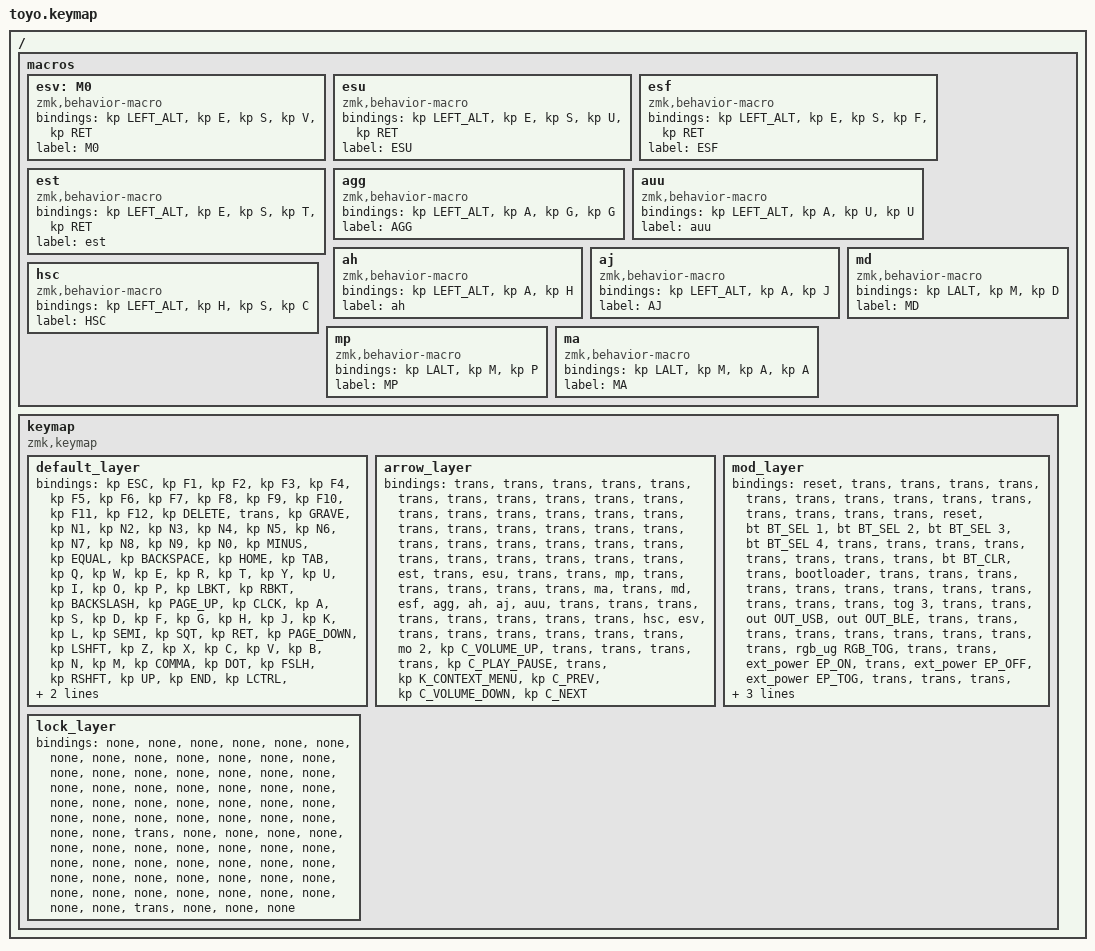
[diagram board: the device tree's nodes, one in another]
/*
 * Copyright (c) 2021 Nick Winans
 *
 * SPDX-License-Identifier: MIT
 */

#include <behaviors.dtsi>
#include <dt-bindings/zmk/bt.h>
#include <dt-bindings/zmk/ext_power.h>
#include <dt-bindings/zmk/keys.h>
#include <dt-bindings/zmk/outputs.h>
#include <dt-bindings/zmk/rgb.h>

/ {
    macros {
        esv: M0 {
            compatible = "zmk,behavior-macro";
            #binding-cells = <0>;
            bindings = <&kp LEFT_ALT &kp E &kp S &kp V &kp RET>;
            label = "M0";
        };

        esu: esu {
            compatible = "zmk,behavior-macro";
            #binding-cells = <0>;
            bindings = <&kp LEFT_ALT &kp E &kp S &kp U &kp RET>;
            label = "ESU";
        };

        esf: esf {
            compatible = "zmk,behavior-macro";
            #binding-cells = <0>;
            bindings = <&kp LEFT_ALT &kp E &kp S &kp F &kp RET>;
            label = "ESF";
        };

        est: est {
            compatible = "zmk,behavior-macro";
            #binding-cells = <0>;
            bindings = <&kp LEFT_ALT &kp E &kp S &kp T &kp RET>;
            label = "est";
        };

        agg: agg {
            compatible = "zmk,behavior-macro";
            #binding-cells = <0>;
            bindings = <&kp LEFT_ALT &kp A &kp G &kp G>;
            label = "AGG";
        };

        auu: auu {
            compatible = "zmk,behavior-macro";
            #binding-cells = <0>;
            bindings = <&kp LEFT_ALT &kp A &kp U &kp U>;
            label = "auu";
        };

        ah: ah {
            compatible = "zmk,behavior-macro";
            #binding-cells = <0>;
            bindings = <&kp LEFT_ALT &kp A &kp H>;
            label = "ah";
        };

        aj: aj {
            compatible = "zmk,behavior-macro";
            #binding-cells = <0>;
            bindings = <&kp LEFT_ALT &kp A &kp J>;
            label = "AJ";
        };

        hsc: hsc {
            compatible = "zmk,behavior-macro";
            #binding-cells = <0>;
            bindings = <&kp LEFT_ALT &kp H &kp S &kp C>;
            label = "HSC";
        };

        md: md {
            compatible = "zmk,behavior-macro";
            #binding-cells = <0>;
            bindings = <&kp LALT &kp M &kp D>;
            label = "MD";
        };

        mp: mp {
            compatible = "zmk,behavior-macro";
            #binding-cells = <0>;
            bindings = <&kp LALT &kp M &kp P>;
            label = "MP";
        };

        ma: ma {
            compatible = "zmk,behavior-macro";
            #binding-cells = <0>;
            bindings = <&kp LALT &kp M &kp A &kp A>;
            label = "MA";
        };
    };

    keymap {
        compatible = "zmk,keymap";

        default_layer {
            // ----------------------------------------------------------------------------------------------------------
            // | F1  | ESC |  1  |  2  |  3  |  4  |  5  |  6  |  7  |  8  |  9  |  0  |  -  |  =  |   BKSP   | HOME    |
            // | F2  | TAB  |  Q  |  W  |  E  |  R  |  T  |  Y  |  U  |  I  |  O  |  P  |  [  |  ]  |   "|"   | PG UP   |
            // | F3  | CAPS  |  A  |  S  | D  |  F  |  G  |  H  |  J  |  K  |  L  |  ;  |  '  |     ENTER     | PG DOWN |
            // | F4  |  SHIFT | SHIFT |  Z  |  X  |  C  |  V  |  B  |  N  |  M  |  ,  |  .  |  /  |   SHIFT  |  UP   | END     |
            // | F5  |  CTL  |  ALT  |  WIN  |                SPACE MO(1)   | MO(1)|  MO(2)  |  LEFT  |  DOWN | RIGHT   |
            // ----------------------------------------------------------------------------------------------------------

            bindings = <
&kp ESC  &kp F1  &kp F2  &kp F3  &kp F4  &kp F5  &kp F6  &kp F7  &kp F8  &kp F9  &kp F10  &kp F11  &kp F12  &kp DELETE  &trans  &kp GRAVE  &kp N1  &kp N2  &kp N3  &kp N4  &kp N5  &kp N6  &kp N7  &kp N8  &kp N9  &kp N0  &kp MINUS  &kp EQUAL  &kp BACKSPACE  &kp HOME  &kp TAB  &kp Q  &kp W  &kp E  &kp R  &kp T  &kp Y  &kp U  &kp I  &kp O  &kp P  &kp LBKT  &kp RBKT  &kp BACKSLASH  &kp PAGE_UP  &kp CLCK  &kp A  &kp S  &kp D  &kp F  &kp G  &kp H  &kp J  &kp K  &kp L  &kp SEMI  &kp SQT  &kp RET  &kp PAGE_DOWN  &kp LSHFT  &kp Z  &kp X  &kp C  &kp V  &kp B  &kp N  &kp M  &kp COMMA  &kp DOT  &kp FSLH  &kp RSHFT  &kp UP  &kp END  &kp LCTRL  &kp LEFT_WIN  &kp LEFT_ALT  &kp SPACE  &mo 1  &kp RIGHT_CONTROL  &kp LEFT  &kp DOWN  &kp RIGHT
            >;
        };

        arrow_layer {
            // ----------------------------------------------------------------------------------------------------------------
            // |        |    |     |     |     |     |     |     |     |     |     |     |     |     |     |   `~    |
            // |        |    |     |     |     |     |     |     |     |     |     |     |     |     |     |         |
            // |        |    |     |     |     |     |     |LEFT |DOWN |  UP |RIGHT|     |     |     |     |         |
            // |        |    |     |     |     |     |     |     |     |     |     |     |     |     |     |         |
            // |        |    |     |     |                                               |     |     |     |         |
            // ----------------------------------------------------------------------------------------------------------------

            bindings = <
&trans  &trans  &trans  &trans  &trans  &trans  &trans  &trans  &trans  &trans  &trans  &trans  &trans  &trans  &trans  &trans  &trans  &trans  &trans  &trans  &trans  &trans  &trans  &trans  &trans  &trans  &trans  &trans  &trans  &trans  &trans  &trans  &trans  &trans  &trans  &est  &trans  &esu  &trans  &trans  &mp  &trans  &trans  &trans  &trans  &trans  &ma  &trans  &md  &esf  &agg  &ah  &aj  &auu  &trans  &trans  &trans  &trans  &trans  &trans  &trans  &trans  &hsc  &esv  &trans  &trans  &trans  &trans  &trans  &trans  &mo 2  &kp C_VOLUME_UP  &trans  &trans  &trans  &trans  &kp C_PLAY_PAUSE  &trans  &kp K_CONTEXT_MENU  &kp C_PREV  &kp C_VOLUME_DOWN  &kp C_NEXT
            >;
        };

        mod_layer {
            // ----------------------------------------------------------------------------------------------------------------
            // |        |    | BT 1|BT 2 |BT 3 |BT 4 |     |     |     |     |     |     |     |     |BT CLR |         |
            // |        |    | RST | BOOT|     |     |     |     |     |     |     |     |     |     |       |         |
            // |        |    | USB | BLE |     |     |     |     |     |     |     |     |     |     |RGB TOG|         |
            // |        |    |EP_ON|EP_OFF|EP_TOG|     |     |     |     |     |     |     |     |     |       |         |
            // |        |    |     |     |                                               |     |     |       |         |
            // ----------------------------------------------------------------------------------------------------------------

            bindings = <
&reset  &trans  &trans  &trans  &trans  &trans  &trans  &trans  &trans  &trans  &trans  &trans  &trans  &trans  &trans  &reset  &bt BT_SEL 1  &bt BT_SEL 2  &bt BT_SEL 3  &bt BT_SEL 4  &trans  &trans  &trans  &trans  &trans  &trans  &trans  &trans  &bt BT_CLR  &trans  &bootloader  &trans  &trans  &trans  &trans  &trans  &trans  &trans  &trans  &trans  &trans  &trans  &trans  &tog 3  &trans  &trans  &out OUT_USB  &out OUT_BLE  &trans  &trans  &trans  &trans  &trans  &trans  &trans  &trans  &trans  &rgb_ug RGB_TOG  &trans  &trans  &ext_power EP_ON  &trans  &ext_power EP_OFF  &ext_power EP_TOG  &trans  &trans  &trans  &trans  &trans  &trans  &trans  &trans  &trans  &trans  &trans  &trans  &trans  &trans  &trans  &trans  &trans  &trans
            >;
        };

        lock_layer {
            bindings = <
&none  &none  &none  &none  &none  &none  &none  &none  &none  &none  &none  &none  &none  &none  &none  &none  &none  &none  &none  &none  &none  &none  &none  &none  &none  &none  &none  &none  &none  &none  &none  &none  &none  &none  &none  &none  &none  &none  &none  &none  &none  &none  &none  &trans  &none  &none  &none  &none  &none  &none  &none  &none  &none  &none  &none  &none  &none  &none  &none  &none  &none  &none  &none  &none  &none  &none  &none  &none  &none  &none  &none  &none  &none  &none  &none  &none  &none  &none  &trans  &none  &none  &none
            >;
        };
    };
};
